AUTOSAR XML (schema 00046)
package /ComponentTypes
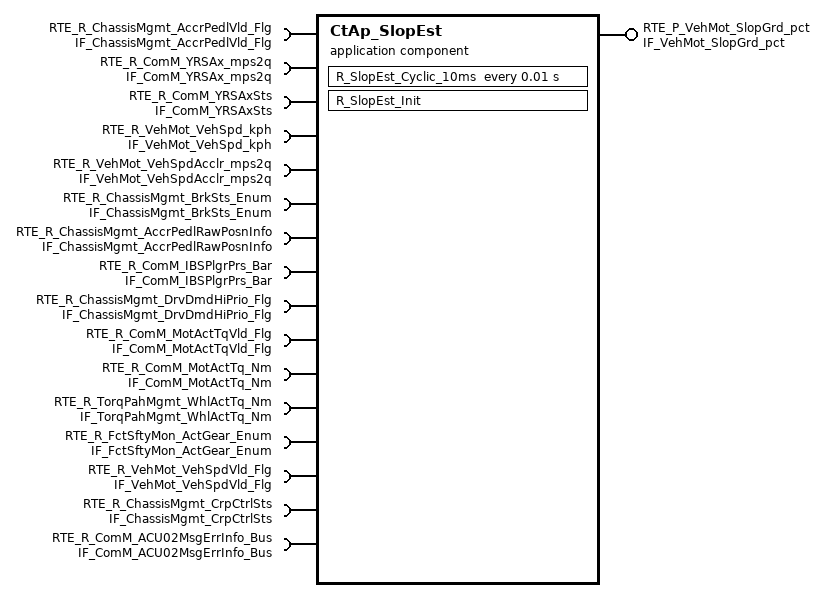
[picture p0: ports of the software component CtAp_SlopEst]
  application sw component type CtAp_SlopEst
    require port RTE_R_ChassisMgmt_AccrPedlVld_Flg: nonqueued-receiver-com-spec{data-element=tec_ChassisMgmt_AccrPedlVld_Flg, filter=data-filter-type=ALWAYS, init-value=0}, required-interface=IF_ChassisMgmt_AccrPedlVld_Flg
    provide port RTE_P_VehMot_SlopGrd_pct: nonqueued-sender-com-spec{data-element=tec_VehMot_SlopGrd_pct, init-value=0}, provided-interface=IF_VehMot_SlopGrd_pct
    15 x require port:
      RTE_R_ComM_YRSAx_mps2q: nonqueued-receiver-com-spec{data-element=tec_ComM_YRSAx_mps2q, filter=data-filter-type=ALWAYS, init-value=0}, required-interface=IF_ComM_YRSAx_mps2q
      RTE_R_ComM_YRSAxSts: nonqueued-receiver-com-spec{data-element=tec_ComM_YRSAxSts, filter=data-filter-type=ALWAYS, init-value=0}, required-interface=IF_ComM_YRSAxSts
      RTE_R_VehMot_VehSpd_kph: nonqueued-receiver-com-spec{data-element=tec_VehMot_VehSpd_kph, filter=data-filter-type=ALWAYS, init-value=0}, required-interface=IF_VehMot_VehSpd_kph
      RTE_R_VehMot_VehSpdAcclr_mps2q: nonqueued-receiver-com-spec{data-element=tec_VehMot_VehSpdAcclr_mps2q, filter=data-filter-type=ALWAYS, init-value=0}, required-interface=IF_VehMot_VehSpdAcclr_mps2q
      RTE_R_ChassisMgmt_BrkSts_Enum: nonqueued-receiver-com-spec{data-element=tec_ChassisMgmt_BrkSts_Enum, filter=data-filter-type=ALWAYS, init-value=0}, required-interface=IF_ChassisMgmt_BrkSts_Enum
      RTE_R_ChassisMgmt_AccrPedlRawPosnInfo: nonqueued-receiver-com-spec{data-element=tec_ChassisMgmt_AccrPedlRawPosnInfo, filter=data-filter-type=ALWAYS, init-value=0}, required-interface=IF_ChassisMgmt_AccrPedlRawPosnInfo
      RTE_R_ComM_IBSPlgrPrs_Bar: nonqueued-receiver-com-spec{data-element=tec_ComM_IBSPlgrPrs_Bar, filter=data-filter-type=ALWAYS, init-value=0}, required-interface=IF_ComM_IBSPlgrPrs_Bar
      RTE_R_ChassisMgmt_DrvDmdHiPrio_Flg: nonqueued-receiver-com-spec{data-element=tec_ChassisMgmt_DrvDmdHiPrio_Flg, filter=data-filter-type=ALWAYS, init-value=0}, required-interface=IF_ChassisMgmt_DrvDmdHiPrio_Flg
      RTE_R_ComM_MotActTqVld_Flg: nonqueued-receiver-com-spec{data-element=tec_ComM_MotActTqVld_Flg, filter=data-filter-type=ALWAYS, init-value=0}, required-interface=IF_ComM_MotActTqVld_Flg
      RTE_R_ComM_MotActTq_Nm: nonqueued-receiver-com-spec{data-element=tec_ComM_MotActTq_Nm, filter=data-filter-type=ALWAYS, init-value=0}, required-interface=IF_ComM_MotActTq_Nm
      RTE_R_TorqPahMgmt_WhlActTq_Nm: nonqueued-receiver-com-spec{data-element=tec_TorqPahMgmt_WhlActTq_Nm, filter=data-filter-type=ALWAYS, init-value=0}, required-interface=IF_TorqPahMgmt_WhlActTq_Nm
      RTE_R_FctSftyMon_ActGear_Enum: nonqueued-receiver-com-spec{data-element=tec_FctSftyMon_ActGear_Enum, filter=data-filter-type=ALWAYS, init-value=0}, required-interface=IF_FctSftyMon_ActGear_Enum
      RTE_R_VehMot_VehSpdVld_Flg: nonqueued-receiver-com-spec{data-element=tec_VehMot_VehSpdVld_Flg, filter=data-filter-type=ALWAYS, init-value=0}, required-interface=IF_VehMot_VehSpdVld_Flg
      RTE_R_ChassisMgmt_CrpCtrlSts: nonqueued-receiver-com-spec{data-element=tec_ChassisMgmt_CrpCtrlSts, filter=data-filter-type=ALWAYS, init-value=0}, required-interface=IF_ChassisMgmt_CrpCtrlSts
      RTE_R_ComM_ACU02MsgErrInfo_Bus: required-interface=IF_ComM_ACU02MsgErrInfo_Bus
        required-com-specs:
          data-element=tec_ComM_ACU02CRCDTCInfo_Bus, filter=data-filter-type=ALWAYS, init-value=fields=[ComM_MonStatACU02CRCDTCErrorInfo:0, ComM_MonResACU02CRCDTCErrorInfo:0, ComM_ErrStatACU02CRCDTCErrorInfo:0, ComM_ErrResACU02CRCDTCErrorInfo:0]
          data-element=tec_ComM_ACU02TimeoutDTCInfo_Bus, filter=data-filter-type=ALWAYS, init-value=fields=[ComM_MonStatACU02TimeoutDTCInfo:0, ComM_MonResACU02TimeoutDTCInfo:0, ComM_ErrStatACU02TimeoutDTCInfo:0, ComM_ErrResACU02TimeoutDTCInfo:0]
          data-element=tec_ComM_ACU02TimeoutInfo_Bus, filter=data-filter-type=ALWAYS, init-value=fields=[ComM_MonStatACU02TimeoutInfo:0, ComM_MonResACU02TimeoutInfo:0, ComM_ErrStatACU02TimeoutInfo:0, ComM_ErrResACU02TimeoutInfo:0]
    behavior CtAp_SlopEst_InternalBehavior
      timing event TMT_R_SlopEst_Cyclic_10ms: start-on-event=R_SlopEst_Cyclic_10ms, period=0.01
      init event CtAp_SlopEst_InitEvent: start-on-event=R_SlopEst_Init
      runnable R_SlopEst_Cyclic_10ms
        data-receive-point-by-arguments:
          16 x access:
            REC_RTE_R_ChassisMgmt_AccrPedlVld_Flg_tec_ChassisMgmt_AccrPedlVld_Flg: accessed-variable=RTE_R_ChassisMgmt_AccrPedlVld_Flg.tec_ChassisMgmt_AccrPedlVld_Flg
            REC_RTE_R_ComM_YRSAxSts_Flg_tec_ComM_YRSAxSts_Flg: accessed-variable=RTE_R_ComM_YRSAxSts.tec_ComM_YRSAxSts
            REC_RTE_R_ComM_YRSAx_mps2q_tec_ComM_YRSAx_mps2q: accessed-variable=RTE_R_ComM_YRSAx_mps2q.tec_ComM_YRSAx_mps2q
            REC_RTE_R_VehMot_VehSpdAcclr_mps2q_tec_VehMot_VehSpdAcclr_mps2q: accessed-variable=RTE_R_VehMot_VehSpdAcclr_mps2q.tec_VehMot_VehSpdAcclr_mps2q
            REC_RTE_R_VehMot_VehSpd_kph_tec_VehMot_VehSpd_kph: accessed-variable=RTE_R_VehMot_VehSpd_kph.tec_VehMot_VehSpd_kph
            REC_RTE_R_ChassisMgmt_BrkSts_Enum_tec_ChassisMgmt_BrkSts_Enum: accessed-variable=RTE_R_ChassisMgmt_BrkSts_Enum.tec_ChassisMgmt_BrkSts_Enum
            REC_RTE_R_ChassisMgmt_AccrPedlRawPosnInfo_tec_ChassisMgmt_AccrPedlRawPosnInfo: accessed-variable=RTE_R_ChassisMgmt_AccrPedlRawPosnInfo.tec_ChassisMgmt_AccrPedlRawPosnInfo
            REC_RTE_R_ChassisMgmt_CrpCtrlSts_tec_ChassisMgmt_CrpCtrlSts: accessed-variable=RTE_R_ChassisMgmt_CrpCtrlSts.tec_ChassisMgmt_CrpCtrlSts
            REC_RTE_R_ChassisMgmt_DrvDmdHiPrio_Flg_tec_ChassisMgmt_DrvDmdHiPrio_Flg: accessed-variable=RTE_R_ChassisMgmt_DrvDmdHiPrio_Flg.tec_ChassisMgmt_DrvDmdHiPrio_Flg
            REC_RTE_R_ComM_IBSPlgrPrs_Bar_tec_ComM_IBSPlgrPrs_Bar: accessed-variable=RTE_R_ComM_IBSPlgrPrs_Bar.tec_ComM_IBSPlgrPrs_Bar
            REC_RTE_R_ComM_MotActTqVld_Flg_tec_ComM_MotActTqVld_Flg: accessed-variable=RTE_R_ComM_MotActTqVld_Flg.tec_ComM_MotActTqVld_Flg
            REC_RTE_R_ComM_MotActTq_Nm_tec_ComM_MotActTq_Nm: accessed-variable=RTE_R_ComM_MotActTq_Nm.tec_ComM_MotActTq_Nm
            REC_RTE_R_FctSftyMon_ActGear_Enum_tec_FctSftyMon_ActGear_Enum: accessed-variable=RTE_R_FctSftyMon_ActGear_Enum.tec_FctSftyMon_ActGear_Enum
            REC_RTE_R_TorqPahMgmt_WhlActTq_Nm_tec_TorqPahMgmt_WhlActTq_Nm: accessed-variable=RTE_R_TorqPahMgmt_WhlActTq_Nm.tec_TorqPahMgmt_WhlActTq_Nm
            REC_RTE_R_VehMot_VehSpdVld_Flg_tec_VehMot_VehSpdVld_Flg: accessed-variable=RTE_R_VehMot_VehSpdVld_Flg.tec_VehMot_VehSpdVld_Flg
            REC_RTE_R_ComM_ACU02MsgErrInfo_Bus_tec_ComM_ACU02TimeoutInfo_Bus: accessed-variable=RTE_R_ComM_ACU02MsgErrInfo_Bus.tec_ComM_ACU02TimeoutInfo_Bus
        data-send-points:
          access SEND_RTE_P_VehMot_SlopGrd_pct_tec_VehMot_SlopGrd_pct: accessed-variable=RTE_P_VehMot_SlopGrd_pct.tec_VehMot_SlopGrd_pct
      runnable R_SlopEst_Init
  swc implementation CtAp_SlopEst_Implementation: behavior=CtAp_SlopEst_InternalBehavior
